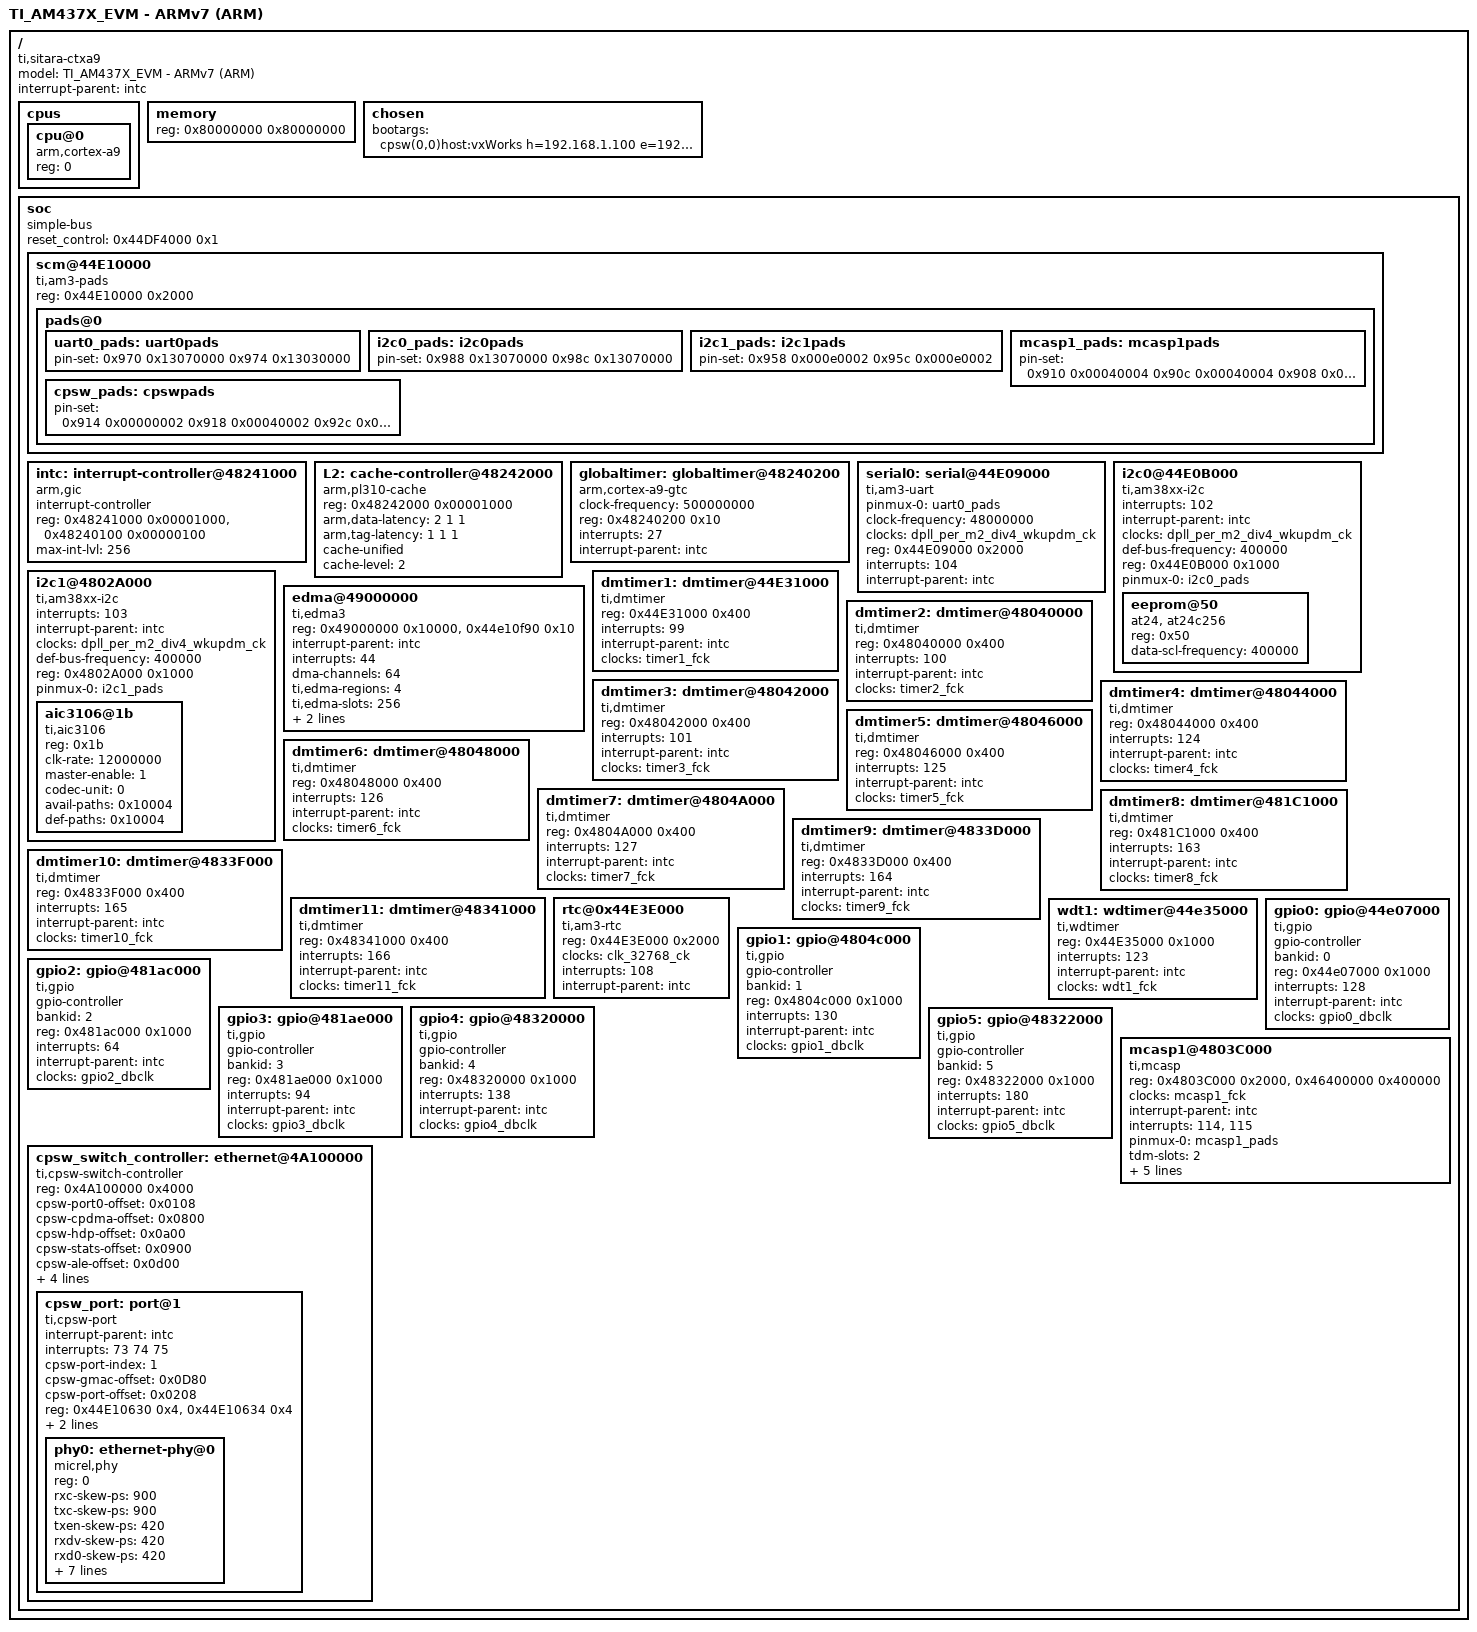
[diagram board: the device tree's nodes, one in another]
/* am437x-evm.dts - TI AM437X EVM device tree source */

/*
modification history
--------------------
27oct16,wch  added RTC alarm support (F6376)
11may16,sye  use def-bus-frequency to set default I2C BUS speed (US76156)
30dec15,m_w  update cpsw driver to make each port use independent interrupt
             resource. (V7PRO-2729)
09sep15,swu  changed the default IP address. (V7PRO-2003)
10aug15,swu  moved data-scl-frequency to DTS. (V7PRO-2323)
23sep14,m_w  make reboot stable.(V7PRO-1269)
01jun14,swu  created (US40646)
*/

/dts-v1/;

/include/ "am437x-clocks.dtsi" /* clock node tree system */

/   {
    model = "TI_AM437X_EVM - ARMv7 (ARM)";
    compatible = "ti,sitara-ctxa9";
    #address-cells = <1>;
    #size-cells = <1>;
    interrupt-parent = <&intc>;

    cpus
        {
        #size-cells = <0>;
        #address-cells = <1>;

        cpu@0
            {
            device_type = "cpu";
            compatible = "arm,cortex-a9";
            reg = <0>;
            };
        };

    memory
        {
        device_type = "memory";
        reg = <0x80000000 0x80000000>; /* on board 2GB */
        };

    chosen
        {
        bootargs = "cpsw(0,0)host:vxWorks h=192.168.1.100 e=192.168.1.10:ffffff00 u=vxWorks pw=vxTarget f=0x0";
        };

    soc
        {
        compatible = "simple-bus";
        device_type = "soc";
        #address-cells = <1>;
        #size-cells = <1>;
        reset_control = <0x44DF4000 0x1>; /* PRCM_PRM_RSTCTRL Register, which 
                                           * was used to reset whole SOC */
        ranges;

        scm@44E10000     /* control module */
            {
            /* this device provide pads config */
            compatible = "ti,am3-pads";
            reg = <0x44E10000 0x2000>;
            #address-cells = <1>;
            #size-cells = <0>;
            pads@0
                {
                uart0_pads: uart0pads
                    {
                    pin-set = <
                              0x970 0x13070000 /* PIN_UART0_RXD */
                              0x974 0x13030000 /* PIN_UART0_TXD */
                              >;
                    };

                i2c0_pads: i2c0pads
                    {
                    pin-set = <
                              0x988 0x13070000 /* PIN_I2C0_SDA */
                              0x98c 0x13070000 /* PIN_I2C0_SCL */
                              >;
                    };

                i2c1_pads: i2c1pads
                    {
                    pin-set = <
                              0x958 0x000e0002 /* PIN_I2C1_SDA */
                              0x95c 0x000e0002 /* PIN_I2C1_SCL */
                              >;
                    };

                mcasp1_pads: mcasp1pads
                    {
                    pin-set = <
                              0x910 0x00040004 /* mii1-rxerr */
                              0x90c 0x00040004 /* mii1-crs */
                              0x908 0x00000004 /* mii1-col */
                              0x944 0x00040004 /* mii1-ref-clk */
                              >;
                    };
                    
                cpsw_pads: cpswpads
                    {
                    pin-set = <
                              0x914 0x00000002 /* CTRL_CONF_MII1_TXEN */
                              0x918 0x00040002 /* CTRL_CONF_MII1_RXDV */
                              0x92c 0x00000002 /* CTRL_CONF_MII1_TXCLK */
                              0x930 0x00040002 /* CTRL_CONF_MII1_RXCLK */
                              0x928 0x00000002 /* CTRL_CONF_MII1_TXD0 */
                              0x924 0x00000002 /* CTRL_CONF_MII1_TXD1 */
                              0x920 0x00000002 /* CTRL_CONF_MII1_TXD2 */
                              0x91c 0x00000002 /* CTRL_CONF_MII1_TXD3 */
                              0x940 0x00040002 /* CTRL_CONF_MII1_RXD0 */
                              0x93c 0x00040002 /* CTRL_CONF_MII1_RXD1 */
                              0x938 0x00040002 /* CTRL_CONF_MII1_RXD2 */
                              0x934 0x00040002 /* CTRL_CONF_MII1_RXD3 */
                              
                              0x840 0x08040007 /* CTRL_CONF_MII2_TXEN */
                              0x844 0x08040007 /* CTRL_CONF_MII2_RXDV */
                              0x858 0x08040007 /* CTRL_CONF_MII2_TXCLK */
                              0x85c 0x08040007 /* CTRL_CONF_MII2_RXCLK */
                              0x854 0x08040007 /* CTRL_CONF_MII2_TXD0 */
                              0x850 0x08040007 /* CTRL_CONF_MII2_TXD1 */
                              0x84c 0x08040007 /* CTRL_CONF_MII2_TXD2 */
                              0x848 0x08040007 /* CTRL_CONF_MII2_TXD3 */
                              0x86c 0x08040007 /* CTRL_CONF_MII2_RXD0 */
                              0x868 0x08040007 /* CTRL_CONF_MII2_RXD1 */
                              0x864 0x08040007 /* CTRL_CONF_MII2_RXD2 */
                              0x860 0x08040007 /* CTRL_CONF_MII2_RXD3 */

                              0x650 0x0000000a /* CTRL_GMII_SEL, RGMII mode*/
                              >;
                    };                      
                };
            };

        intc: interrupt-controller@48241000
            {
            compatible = "arm,gic";
            #interrupt-cells = <1>;
            #address-cells = <1>;
            interrupt-controller;
            reg = <0x48241000 0x00001000>,  /* MPU Interrupt Controller Interfaces */
                  <0x48240100 0x00000100>;  /* MPU Interrupt Distributor */                  
            max-int-lvl = <256>;
            };

        L2: cache-controller@48242000
            {
            compatible = "arm,pl310-cache";
            reg = <0x48242000 0x00001000>;
            arm,data-latency = <2 1 1>;
            arm,tag-latency = <1 1 1>;
            cache-unified;
            cache-level = <2>;
            };

        globaltimer: globaltimer@48240200
            {
            compatible = "arm,cortex-a9-gtc";
            clock-frequency = <500000000>;
            reg = <0x48240200 0x10>;
            interrupts = <27>;
            interrupt-parent = <&intc>;
            };
            
        serial0: serial@44E09000
            {
            compatible = "ti,am3-uart", "arm,ns16550";
            pinmux-0 = <&uart0_pads>;
            clock-frequency = <48000000>;
            clocks = <&dpll_per_m2_div4_wkupdm_ck>;       
            reg = <0x44E09000 0x2000>;
            interrupts = <104>;
            interrupt-parent = <&intc>;
            };
            
        i2c0@44E0B000
            {
            #address-cells = <1>;
            #size-cells = <0>;
            compatible = "ti,am38xx-i2c";
            interrupts = <102>;
            interrupt-parent = <&intc>;              
            clocks = <&dpll_per_m2_div4_wkupdm_ck>;
            def-bus-frequency = <400000>;
            reg = <0x44E0B000 0x1000>;
            pinmux-0 = <&i2c0_pads>;

            eeprom@50
                {
                compatible = "at24, at24c256";
                reg = <0x50>;
                data-scl-frequency = <400000>;
                };
            };

        i2c1@4802A000
            {
            #address-cells = <1>;
            #size-cells = <0>;
            compatible = "ti,am38xx-i2c";
            interrupts = <103>;
            interrupt-parent = <&intc>; 
            clocks = <&dpll_per_m2_div4_wkupdm_ck>;
            def-bus-frequency = <400000>;
            reg = <0x4802A000 0x1000>;
            pinmux-0 = <&i2c1_pads>;

            aic3106@1b
                {
                compatible = "ti,aic3106";
                reg = <0x1b>;
                clk-rate = <12000000>;
                master-enable = <1>;
                codec-unit = <0>;
                avail-paths = <0x10004>;
                def-paths = <0x10004>;
                };
            };

        edma@49000000
            {
            reg = <0x49000000 0x10000>,
                  <0x44e10f90 0x10>;
            interrupt-parent = <&intc>;
            interrupts = <44>;
            compatible = "ti,edma3";
            #dma-cells = <1>;
            dma-channels = <64>;
            ti,edma-regions = <4>;
            ti,edma-slots = <256>;
            clocks = <&ttcp_ick>,<&tptc0_ick>,<&tptc1_ick>,<&tptc2_ick>;
            clock-names = "ttcp_ick","tptc0_ick","tptc1_ick","tptc2_ick";
            };

        dmtimer1: dmtimer@44E31000      /* DM TImer 1(ms) */
            {
            compatible = "ti,dmtimer";
            #address-cells = <1>;
            #size-cells = <1>;
            reg = <0x44E31000 0x400>;
            interrupts = <99>;
            interrupt-parent = <&intc>;
            clocks = <&timer1_fck>;          
            };

        dmtimer2: dmtimer@48040000      /* DM Timer 2 */
            {
            compatible = "ti,dmtimer";
            #address-cells = <1>;
            #size-cells = <1>;
            reg = <0x48040000 0x400>;
            interrupts = <100>;
            interrupt-parent = <&intc>;
            clocks = <&timer2_fck>;           
            };

        dmtimer3: dmtimer@48042000      /* DM Timer 3 */
            {
            compatible = "ti,dmtimer";
            #address-cells = <1>;
            #size-cells = <1>;
            reg = <0x48042000 0x400>;
            interrupts = <101>;
            interrupt-parent = <&intc>;
            clocks = <&timer3_fck>;            
            };
            
        dmtimer4: dmtimer@48044000      /* DM Timer 4 */
            {
            compatible = "ti,dmtimer";
            #address-cells = <1>;
            #size-cells = <1>;
            reg = <0x48044000 0x400>;
            interrupts = <124>;
            interrupt-parent = <&intc>;
            clocks = <&timer4_fck>;            
            };
            
        dmtimer5: dmtimer@48046000      /* DM Timer 5 */
            {
            compatible = "ti,dmtimer";
            #address-cells = <1>;
            #size-cells = <1>;
            reg = <0x48046000 0x400>;
            interrupts = <125>;
            interrupt-parent = <&intc>;
            clocks = <&timer5_fck>;            
            };
            
        dmtimer6: dmtimer@48048000      /* DM Timer 6 */
            {
            compatible = "ti,dmtimer";
            #address-cells = <1>;
            #size-cells = <1>;
            reg = <0x48048000 0x400>;
            interrupts = <126>;
            interrupt-parent = <&intc>;
            clocks = <&timer6_fck>;           
            };
            
        dmtimer7: dmtimer@4804A000      /* DM Timer 7 */
            {
            compatible = "ti,dmtimer";
            #address-cells = <1>;
            #size-cells = <1>;
            reg = <0x4804A000 0x400>;
            interrupts = <127>;
            interrupt-parent = <&intc>;
            clocks = <&timer7_fck>;           
            };
            
        dmtimer8: dmtimer@481C1000      /* DM Timer 8 */
            {
            compatible = "ti,dmtimer";
            #address-cells = <1>;
            #size-cells = <1>;
            reg = <0x481C1000 0x400>;
            interrupts = <163>;
            interrupt-parent = <&intc>;
            clocks = <&timer8_fck>;           
            };
            
        dmtimer9: dmtimer@4833D000      /* DM Timer 9 */
            {
            compatible = "ti,dmtimer";
            #address-cells = <1>;
            #size-cells = <1>;
            reg = <0x4833D000 0x400>;
            interrupts = <164>;
            interrupt-parent = <&intc>;
            clocks = <&timer9_fck>;           
            };
            
        dmtimer10: dmtimer@4833F000     /* DM Timer 10 */
            {
            compatible = "ti,dmtimer";
            #address-cells = <1>;
            #size-cells = <1>;
            reg = <0x4833F000 0x400>;
            interrupts = <165>;
            interrupt-parent = <&intc>;
            clocks = <&timer10_fck>;            
            };
            
        dmtimer11: dmtimer@48341000     /* DM Timer 11 */
            {
            compatible = "ti,dmtimer";
            #address-cells = <1>;
            #size-cells = <1>;
            reg = <0x48341000 0x400>;
            interrupts = <166>;
            interrupt-parent = <&intc>;
            clocks = <&timer11_fck>;            
            }; 
 
        rtc@0x44E3E000                  /* RTC */
            {
            compatible = "ti,am3-rtc";
            reg = <0x44E3E000 0x2000>;
            clocks = <&clk_32768_ck>;
            interrupts = <108>;
            interrupt-parent = <&intc>;            
            };
            
        wdt1: wdtimer@44e35000          /* watchdog timer 1 */
            {
            compatible = "ti,wdtimer";
            #address-cells = <1>;
            #size-cells = <1>;
            reg = <0x44E35000 0x1000>;
            interrupts = <123>;
            interrupt-parent = <&intc>;
            clocks = <&wdt1_fck>;            
            };  

        gpio0: gpio@44e07000
            {
            compatible = "ti,gpio";
            gpio-controller;
            #gpio-cells = <4>;
            #interrupt-cells = <1>;
            bankid = <0>;
            reg = <0x44e07000 0x1000>;
            interrupts = <128>;
            interrupt-parent = <&intc>;
            clocks = <&gpio0_dbclk>;
            };

        gpio1: gpio@4804c000
            {
            compatible = "ti,gpio";
            gpio-controller;
            #gpio-cells = <4>;
            #interrupt-cells = <1>;
            bankid = <1>;
            reg = <0x4804c000 0x1000>;
            interrupts = <130>;
            interrupt-parent = <&intc>;
            clocks = <&gpio1_dbclk>;
            };

        gpio2: gpio@481ac000
            {
            compatible = "ti,gpio";
            gpio-controller;
            #gpio-cells = <4>;
            #interrupt-cells = <1>;
            bankid = <2>;
            reg = <0x481ac000 0x1000>;
            interrupts = <64>;
            interrupt-parent = <&intc>;
            clocks = <&gpio2_dbclk>;
            };

        gpio3: gpio@481ae000
           {
           compatible = "ti,gpio";
           gpio-controller;
           #gpio-cells = <4>;
           #interrupt-cells = <1>;
           bankid = <3>;
           reg = <0x481ae000 0x1000>;
           interrupts = <94>;
           interrupt-parent = <&intc>;
           clocks = <&gpio3_dbclk>;
           };

        gpio4: gpio@48320000
           {
           compatible = "ti,gpio";
           gpio-controller;
           #gpio-cells = <4>;
           #interrupt-cells = <1>;
           bankid = <4>;
           reg = <0x48320000 0x1000>;
           interrupts = <138>;
           interrupt-parent = <&intc>;
           clocks = <&gpio4_dbclk>;
           };
           
        gpio5: gpio@48322000
           {
           compatible = "ti,gpio";
           gpio-controller;
           #gpio-cells = <4>;
           #interrupt-cells = <1>;
           bankid = <5>;
           reg = <0x48322000 0x1000>;
           interrupts = <180>;
           interrupt-parent = <&intc>;
           clocks = <&gpio5_dbclk>;
           };

        cpsw_switch_controller: ethernet@4A100000     /* ethernet switch controller */
            {
            compatible = "ti,cpsw-switch-controller"; /* switch controller device */
            #address-cells = <1>;
            #size-cells = <1>;

            reg = <0x4A100000 0x4000>;     /* CPSW register space */
            cpsw-port0-offset = <0x0108>;  /* offset - Ethernet Switch Port Control of port0 */
            cpsw-cpdma-offset = <0x0800>;  /* offset - CPPI DMA Controller Module */
            cpsw-hdp-offset   = <0x0a00>;  /* offset - HDP */
            cpsw-stats-offset = <0x0900>;  /* offset - Ethernet Statistics */
            cpsw-ale-offset   = <0x0d00>;  /* offset - Ethernet Address Lookup Engine */
            cpsw-mdio-offset  = <0x1000>;  /* offset - Ethernet MDIO Controller */
            cpsw-wr-offset    = <0x1200>;  /* offset - Ethernet Subsystem Wrapper for RMII/RGMII */

            pinmux-0    = <&cpsw_pads>;
            clocks      = <&cpsw_125mhz_gclk>, <&cpsw_cpts_rft_clk>;
            clock-names = "cpsw_125mhz_gclk","cpsw_cpts_rft_clk";

            cpsw_port: port@1              /* port device*/
                {
                device_type = "network";
                compatible  = "ti,cpsw-port";
                #address-cells    = <1>;
                #size-cells       = <0>;

                interrupt-parent = <&intc>;
                interrupts = <
                             73            /* CPSW (Ethernet) c0_rx_pend */
                             74            /* CPSW (Ethernet) c0_tx_pend */
                             75            /* CPSW (Ethernet) c0_misc_pend */
                             >;

                cpsw-port-index   = <1>;
                cpsw-gmac-offset  = <0x0D80>;      /* offset - Ethernet gmac offset */
                cpsw-port-offset  = <0x0208>;      /* offset - Ethernet Port Control of port1 */
                
                /* 
                 * The mac address will be fetched out from CTRL_MAC_ID with 
                 * higher priority than local-mac-address, each board has an 
                 * unique address for each mac port which was saved in 
                 * CTRL_MAC_ID, if this area was not supplied or it does not
                 * exist, the mac address will be fetched out from
                 * local-mac-address area. Please be careful to use 
                 * local-mac-address with more than one boards in same LAN, DO
                 * NOT use the same local-mac-address value with each board for
                 * it will lead ARP confict in same LAN.
                 * When the CTRL_MAC_ID area and local-mac-address was supplied
                 * simultaneously(here is an example), CTRL_MAC_ID win which
                 * means mac address will be fetched out from CTRL_MAC_ID in
                 * stead of local-mac-address. 
                 */
                reg = <0x44E10630 0x4>,    /* 630h CTRL_MAC_ID0_LO */
                      <0x44E10634 0x4>;    /* 634h CTRL_MAC_ID0_HI */
                local-mac-address = [ 00 40 47 E0 A8 32 ];

                phy-handle = <&phy0>;      /* port1 use phy0 */
                phy0: ethernet-phy@0       /* phy of port0 */
                    {
                    #address-cells = <1>;
                    #size-cells    = <0>;
                    compatible     = "micrel,phy";
                    reg            = <0>;  /* phy address : 0 */
                    rxc-skew-ps    = <900>;/* clock pad skew */
                    txc-skew-ps    = <900>;/* clock pad skew */
                    txen-skew-ps   = <420>;
                    rxdv-skew-ps   = <420>;
                    rxd0-skew-ps   = <420>;
                    rxd1-skew-ps   = <420>;
                    rxd2-skew-ps   = <420>;
                    rxd3-skew-ps   = <420>;
                    txd0-skew-ps   = <420>;
                    txd1-skew-ps   = <420>;
                    txd2-skew-ps   = <420>;
                    txd3-skew-ps   = <420>;                    
                    };
                };/* end of cpsw_port: mac@1 */
            };/* end of cpsw_ma: ethernet@4A100000 */

        mcasp1@4803C000
            {
            compatible = "ti,mcasp";
            reg = <0x4803C000 0x2000>,<0x46400000 0x400000>;
            clocks = <&mcasp1_fck>;
            interrupt-parent = <&intc>;
            interrupts = <114>,<115>;
            pinmux-0 = <&mcasp1_pads>;
            tdm-slots = <2>;
            serial-dir = <
                         /* 0: INACTIVE, 1: TX, 2: RX */
                         0 0 1 2
                         >;
            tx-dma-num = <10>;
            rx-dma-num = <11>;
            master-enable = <0>;
            codec-unit = <0>;
            };         
        };/* end of soc */   
    };/* end of root */
